# ESP32-C6 register map
Vendor: ESPRESSIF SYSTEMS (SHANGHAI) CO., LTD.; Series: ESP32 C-Series; File version: 12
CPU: RV32IMAC r0p0, little endian, no MPU, no FPU, 0 interrupt priority bits
Address unit: 32 bits
Registers are 32-bit, read-write, reset 0x0 unless marked. A register's access mark holds for its fields unless they carry their own. Offsets are from the block's base; [hi:lo] are bit positions; {n}, {i} and the like mark numbered series.

## HP_APM — HP_APM Peripheral
Base 0x60099000
0x00 REGION_FILTER_EN reset 0x1 — Region filter enable register
  [15:0] REGION_FILTER_EN — Region filter enable
{0x4+0xC*i} REGION{i}_ADDR_START (i=0..15) — Region address register
  [31:0] REGION{i}_ADDR_START — Start address of region{i}
{0x8+0xC*i} REGION{i}_ADDR_END reset 0xFFFFFFFF (i=0..15) — Region address register
  [31:0] REGION{i}_ADDR_END — End address of region{i}
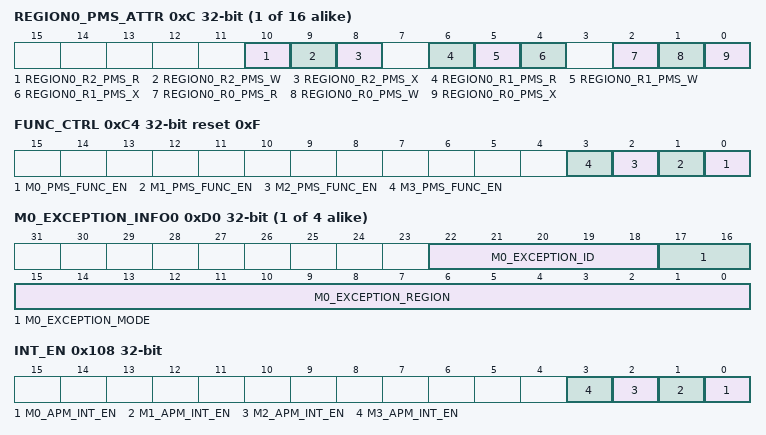
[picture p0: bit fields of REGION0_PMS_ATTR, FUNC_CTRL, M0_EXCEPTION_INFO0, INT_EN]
{0xC+0xC*i} REGION{i}_PMS_ATTR (i=0..15) — Region access authority attribute register
  [10] REGION{i}_R2_PMS_R — Region read authority in REE_MODE2
  [9] REGION{i}_R2_PMS_W — Region write authority in REE_MODE2
  [8] REGION{i}_R2_PMS_X — Region execute authority in REE_MODE2
  [6] REGION{i}_R1_PMS_R — Region read authority in REE_MODE1
  [5] REGION{i}_R1_PMS_W — Region write authority in REE_MODE1
  [4] REGION{i}_R1_PMS_X — Region execute authority in REE_MODE1
  [2] REGION{i}_R0_PMS_R — Region read authority in REE_MODE0
  [1] REGION{i}_R0_PMS_W — Region write authority in REE_MODE0
  [0] REGION{i}_R0_PMS_X — Region execute authority in REE_MODE0
0xC4 FUNC_CTRL reset 0xF — PMS function control register
  [n] M{n}_PMS_FUNC_EN (n=0..3) — PMS M{n} function enable
{0xC8+0x10*i} M{i}_STATUS ro (i=0..3)
  [1:0] M{i}_EXCEPTION_STATUS — Exception status
{0xCC+0x10*i} M{i}_STATUS_CLR wo (i=0..3) — M{i} status clear register
  [0] M{i}_REGION_STATUS_CLR — Clear exception status
{0xD0+0x10*i} M{i}_EXCEPTION_INFO0 ro (i=0..3)
  [22:18] M{i}_EXCEPTION_ID — Exception id information
  [17:16] M{i}_EXCEPTION_MODE — Exception mode
  [15:0] M{i}_EXCEPTION_REGION — Exception region
{0xD4+0x10*i} M{i}_EXCEPTION_INFO1 ro (i=0..3)
  [31:0] M{i}_EXCEPTION_ADDR — Exception addr
0x108 INT_EN — APM interrupt enable register
  [n] M{n}_APM_INT_EN (n=0..3) — APM M{n} interrupt enable
0x10C CLOCK_GATE reset 0x1 — clock gating register
  [0] CLK_EN — reg_clk_en
0x7FC DATE reset 0x2205240 — Version register
  [27:0] DATE — reg_date

## LP_APM — Low-power Access Permission Management Controller
Base 0x600B3800
Registers as HP_APM, without REGION{n}_ADDR_START (n=4..15), REGION{n}_ADDR_END (n=4..15), REGION{n}_PMS_ATTR (n=4..15), M2_STATUS, M2_STATUS_CLR, M2_EXCEPTION_INFO0, M2_EXCEPTION_INFO1, M3_STATUS, M3_STATUS_CLR, M3_EXCEPTION_INFO0, M3_EXCEPTION_INFO1, INT_EN, CLOCK_GATE, DATE; these are added or differ:
0x00 REGION_FILTER_EN reset 0x1 — Region filter enable register
  [3:0] REGION_FILTER_EN — Region filter enable
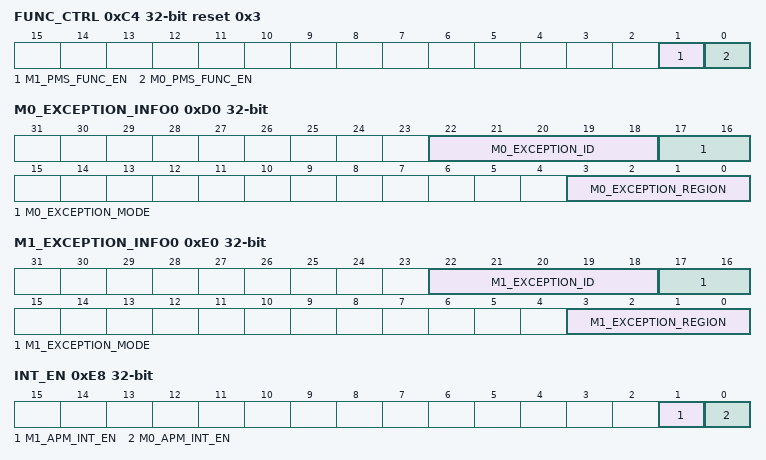
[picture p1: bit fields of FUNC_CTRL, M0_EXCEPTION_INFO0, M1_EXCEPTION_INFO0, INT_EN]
0xC4 FUNC_CTRL reset 0x3 — PMS function control register
  [1] M1_PMS_FUNC_EN — PMS M1 function enable
  [0] M0_PMS_FUNC_EN — PMS M0 function enable
0xD0 M0_EXCEPTION_INFO0 ro
  [22:18] M0_EXCEPTION_ID — Exception id information
  [17:16] M0_EXCEPTION_MODE — Exception mode
  [3:0] M0_EXCEPTION_REGION — Exception region
0xE0 M1_EXCEPTION_INFO0 ro
  [22:18] M1_EXCEPTION_ID — Exception id information
  [17:16] M1_EXCEPTION_MODE — Exception mode
  [3:0] M1_EXCEPTION_REGION — Exception region
0xE8 INT_EN — APM interrupt enable register
  [1] M1_APM_INT_EN — APM M1 interrupt enable
  [0] M0_APM_INT_EN — APM M0 interrupt enable
0xEC CLOCK_GATE reset 0x1 — clock gating register
  [0] CLK_EN — reg_clk_en
0xFC DATE reset 0x2205240 — Version register
  [27:0] DATE — reg_date

## LP_APM0 — LP_APM0 Peripheral
Base 0x60099800
Registers as LP_APM, without M1_STATUS, M1_STATUS_CLR, M1_EXCEPTION_INFO0, M1_EXCEPTION_INFO1, INT_EN, CLOCK_GATE, DATE; these are added or differ:
0xC4 FUNC_CTRL reset 0x1 — PMS function control register
  [0] M0_PMS_FUNC_EN — PMS M0 function enable
0xD8 INT_EN — APM interrupt enable register
  [0] M0_APM_INT_EN — APM M0 interrupt enable
0xDC CLOCK_GATE reset 0x1 — clock gating register
  [0] CLK_EN — reg_clk_en
0x7FC DATE reset 0x2205240 — Version register
  [27:0] DATE — reg_date
